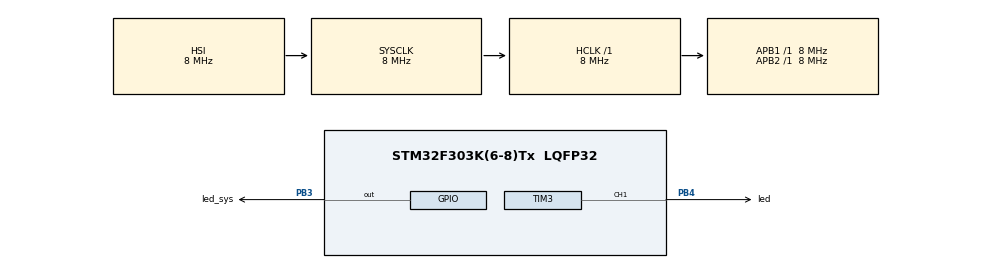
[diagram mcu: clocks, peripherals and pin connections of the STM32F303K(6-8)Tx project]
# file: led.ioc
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FREERTOS.Tasks01=defaultTask,0,128,StartDefaultTask,Default,NULL,Dynamic,NULL,NULL;pwm_task,-3,128,pwmTask,As weak,NULL,Dynamic,NULL,NULL
Mcu.Family=STM32F3
Mcu.Name=STM32F303K(6-8)Tx
Mcu.Package=LQFP32
NVIC.PriorityGroup=NVIC_PRIORITYGROUP_4
PA13.GPIO_Label=SWDIO
PA13.Signal=SYS_JTMS-SWDIO
PA14.GPIO_Label=SWCLK
PA14.Signal=SYS_JTCK-SWCLK
PA15.GPIO_Label=VCP_RX
PA15.Signal=USART2_RX
PA2.GPIO_Label=VCP_TX
PA2.Signal=USART2_TX
PB3.GPIO_Label=led_sys
PB3.Signal=GPIO_Output
PB4.GPIO_Label=led
PB4.GPIO_ModeDefaultPP=GPIO_MODE_AF_PP
PB4.Signal=S_TIM3_CH1
PF0\ /\ OSC_IN.GPIO_Label=MCO
PF0\ /\ OSC_IN.Signal=RCC_OSC_IN
ProjectManager.HeapSize=0x200
ProjectManager.StackSize=0x400
ProjectManager.TargetToolchain=Makefile
RCC.AHBFreq_Value=8000000
RCC.APB1Freq_Value=8000000
RCC.APB1TimFreq_Value=8000000
RCC.APB2Freq_Value=8000000
RCC.CortexFreq_Value=8000000
RCC.HSE_VALUE=8000000
RCC.HSI_VALUE=8000000
RCC.SYSCLKFreq_VALUE=8000000
SH.S_TIM3_CH1.0=TIM3_CH1,PWM Generation1 CH1
TIM3.AutoReloadPreload=TIM_AUTORELOAD_PRELOAD_DISABLE
TIM3.Channel-PWM\ Generation1\ CH1=TIM_CHANNEL_1
TIM3.ClockDivision=TIM_CLOCKDIVISION_DIV1
TIM3.CounterMode=TIM_COUNTERMODE_UP
TIM3.Period=999
TIM3.Prescaler=99
TIM3.Pulse-PWM\ Generation1\ CH1=249
VP_FREERTOS_VS_ENABLE.Mode=Enabled
board=NUCLEO-F303K8

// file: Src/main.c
/**
  ******************************************************************************
  * File Name          : main.c
  * Description        : Main program body
  ******************************************************************************
  * This notice applies to any and all portions of this file
  * that are not between comment pairs USER CODE BEGIN and
  * USER CODE END. Other portions of this file, whether
  * inserted by the user or by software development tools
  * are owned by their respective copyright owners.
  *
  * Copyright (c) 2017 STMicroelectronics International N.V.
  * All rights reserved.
  *
  * Redistribution and use in source and binary forms, with or without
  * modification, are permitted, provided that the following conditions are met:
  *
  * 1. Redistribution of source code must retain the above copyright notice,
  *    this list of conditions and the following disclaimer.
  * 2. Redistributions in binary form must reproduce the above copyright notice,
  *    this list of conditions and the following disclaimer in the documentation
  *    and/or other materials provided with the distribution.
  * 3. Neither the name of STMicroelectronics nor the names of other
  *    contributors to this software may be used to endorse or promote products
  *    derived from this software without specific written permission.
  * 4. This software, including modifications and/or derivative works of this
  *    software, must execute solely and exclusively on microcontroller or
  *    microprocessor devices manufactured by or for STMicroelectronics.
  * 5. Redistribution and use of this software other than as permitted under
  *    this license is void and will automatically terminate your rights under
  *    this license.
  *
  * THIS SOFTWARE IS PROVIDED BY STMICROELECTRONICS AND CONTRIBUTORS "AS IS"
  * AND ANY EXPRESS, IMPLIED OR STATUTORY WARRANTIES, INCLUDING, BUT NOT
  * LIMITED TO, THE IMPLIED WARRANTIES OF MERCHANTABILITY, FITNESS FOR A
  * PARTICULAR PURPOSE AND NON-INFRINGEMENT OF THIRD PARTY INTELLECTUAL PROPERTY
  * RIGHTS ARE DISCLAIMED TO THE FULLEST EXTENT PERMITTED BY LAW. IN NO EVENT
  * SHALL STMICROELECTRONICS OR CONTRIBUTORS BE LIABLE FOR ANY DIRECT, INDIRECT,
  * INCIDENTAL, SPECIAL, EXEMPLARY, OR CONSEQUENTIAL DAMAGES (INCLUDING, BUT NOT
  * LIMITED TO, PROCUREMENT OF SUBSTITUTE GOODS OR SERVICES; LOSS OF USE, DATA,
  * OR PROFITS; OR BUSINESS INTERRUPTION) HOWEVER CAUSED AND ON ANY THEORY OF
  * LIABILITY, WHETHER IN CONTRACT, STRICT LIABILITY, OR TORT (INCLUDING
  * NEGLIGENCE OR OTHERWISE) ARISING IN ANY WAY OUT OF THE USE OF THIS SOFTWARE,
  * EVEN IF ADVISED OF THE POSSIBILITY OF SUCH DAMAGE.
  *
  ******************************************************************************
  */
#include "main.h"
#include "stm32f3xx_hal.h"
#include "cmsis_os.h"

TIM_HandleTypeDef htim3;

osThreadId defaultTaskHandle;
osThreadId pwm_taskHandle;

/* USER CODE BEGIN PV */
/* Private variables ---------------------------------------------------------*/

/* USER CODE END PV */

void SystemClock_Config(void);
static void MX_GPIO_Init(void);
static void MX_TIM3_Init(void);
void StartDefaultTask(void const * argument);
void pwmTask(void const * argument);
void HAL_TIM_MspPostInit(TIM_HandleTypeDef *htim);

/* USER CODE BEGIN PFP */
/* Private function prototypes -----------------------------------------------*/

/* USER CODE END PFP */

int main(void)
{

  /* MCU Configuration----------------------------------------------------------*/

  /* Reset of all peripherals, Initializes the Flash interface and the Systick. */
  HAL_Init();

  /* Configure the system clock */
  SystemClock_Config();

  /* Initialize all configured peripherals */
  MX_GPIO_Init();
  MX_TIM3_Init();

  /* Create the thread(s) */
  /* definition and creation of defaultTask */
  osThreadDef(defaultTask, StartDefaultTask, osPriorityNormal, 0, 128);
  defaultTaskHandle = osThreadCreate(osThread(defaultTask), NULL);

  /* definition and creation of pwm_task */
  osThreadDef(pwm_task, pwmTask, osPriorityIdle, 0, 128);
  pwm_taskHandle = osThreadCreate(osThread(pwm_task), NULL);

  /* Start scheduler */
  osKernelStart();

  /* We should never get here as control is now taken by the scheduler */

  /* Infinite loop */
  while (1)
  {

  }

}

/** System Clock Configuration
*/
void SystemClock_Config(void)
{

  RCC_OscInitTypeDef RCC_OscInitStruct;
  RCC_ClkInitTypeDef RCC_ClkInitStruct;

    /**Initializes the CPU, AHB and APB busses clocks
    */
  RCC_OscInitStruct.OscillatorType = RCC_OSCILLATORTYPE_HSI;
  RCC_OscInitStruct.HSIState = RCC_HSI_ON;
  RCC_OscInitStruct.HSICalibrationValue = 16;
  RCC_OscInitStruct.PLL.PLLState = RCC_PLL_NONE;
  if (HAL_RCC_OscConfig(&RCC_OscInitStruct) != HAL_OK)
  {
    _Error_Handler(__FILE__, __LINE__);
  }

    /**Initializes the CPU, AHB and APB busses clocks
    */
  RCC_ClkInitStruct.ClockType = RCC_CLOCKTYPE_HCLK|RCC_CLOCKTYPE_SYSCLK
                              |RCC_CLOCKTYPE_PCLK1|RCC_CLOCKTYPE_PCLK2;
  RCC_ClkInitStruct.SYSCLKSource = RCC_SYSCLKSOURCE_HSI;
  RCC_ClkInitStruct.AHBCLKDivider = RCC_SYSCLK_DIV1;
  RCC_ClkInitStruct.APB1CLKDivider = RCC_HCLK_DIV1;
  RCC_ClkInitStruct.APB2CLKDivider = RCC_HCLK_DIV1;

  if (HAL_RCC_ClockConfig(&RCC_ClkInitStruct, FLASH_LATENCY_0) != HAL_OK)
  {
    _Error_Handler(__FILE__, __LINE__);
  }

    /**Configure the Systick interrupt time
    */
  HAL_SYSTICK_Config(HAL_RCC_GetHCLKFreq()/1000);

    /**Configure the Systick
    */
  HAL_SYSTICK_CLKSourceConfig(SYSTICK_CLKSOURCE_HCLK);

  /* SysTick_IRQn interrupt configuration */
  HAL_NVIC_SetPriority(SysTick_IRQn, 15, 0);
}

/* TIM3 init function */
static void MX_TIM3_Init(void)
{

  TIM_MasterConfigTypeDef sMasterConfig;
  TIM_OC_InitTypeDef sConfigOC;

  htim3.Instance = TIM3;
  htim3.Init.Prescaler = 99;
  htim3.Init.CounterMode = TIM_COUNTERMODE_UP;
  htim3.Init.Period = 999;
  htim3.Init.ClockDivision = TIM_CLOCKDIVISION_DIV1;
  htim3.Init.AutoReloadPreload = TIM_AUTORELOAD_PRELOAD_DISABLE;
  if (HAL_TIM_PWM_Init(&htim3) != HAL_OK)
  {
    _Error_Handler(__FILE__, __LINE__);
  }

  sMasterConfig.MasterOutputTrigger = TIM_TRGO_RESET;
  sMasterConfig.MasterSlaveMode = TIM_MASTERSLAVEMODE_DISABLE;
  if (HAL_TIMEx_MasterConfigSynchronization(&htim3, &sMasterConfig) != HAL_OK)
  {
    _Error_Handler(__FILE__, __LINE__);
  }

  sConfigOC.OCMode = TIM_OCMODE_PWM1;
  sConfigOC.Pulse = 249;
  sConfigOC.OCPolarity = TIM_OCPOLARITY_HIGH;
  sConfigOC.OCFastMode = TIM_OCFAST_DISABLE;
  if (HAL_TIM_PWM_ConfigChannel(&htim3, &sConfigOC, TIM_CHANNEL_1) != HAL_OK)
  {
    _Error_Handler(__FILE__, __LINE__);
  }

  HAL_TIM_MspPostInit(&htim3);

}

/** Configure pins as
        * Analog
        * Input
        * Output
        * EVENT_OUT
        * EXTI
     PA2   ------> USART2_TX
     PA15   ------> USART2_RX
*/
static void MX_GPIO_Init(void)
{

  GPIO_InitTypeDef GPIO_InitStruct;

  /* GPIO Ports Clock Enable */
  __HAL_RCC_GPIOF_CLK_ENABLE();
  __HAL_RCC_GPIOA_CLK_ENABLE();
  __HAL_RCC_GPIOB_CLK_ENABLE();

  /*Configure GPIO pin Output Level */
  HAL_GPIO_WritePin(led_sys_GPIO_Port, led_sys_Pin, GPIO_PIN_RESET);

  /*Configure GPIO pins : VCP_TX_Pin VCP_RX_Pin */
  GPIO_InitStruct.Pin = VCP_TX_Pin|VCP_RX_Pin;
  GPIO_InitStruct.Mode = GPIO_MODE_AF_PP;
  GPIO_InitStruct.Pull = GPIO_NOPULL;
  GPIO_InitStruct.Speed = GPIO_SPEED_FREQ_HIGH;
  GPIO_InitStruct.Alternate = GPIO_AF7_USART2;
  HAL_GPIO_Init(GPIOA, &GPIO_InitStruct);

  /*Configure GPIO pin : led_sys_Pin */
  GPIO_InitStruct.Pin = led_sys_Pin;
  GPIO_InitStruct.Mode = GPIO_MODE_OUTPUT_PP;
  GPIO_InitStruct.Pull = GPIO_NOPULL;
  GPIO_InitStruct.Speed = GPIO_SPEED_FREQ_LOW;
  HAL_GPIO_Init(led_sys_GPIO_Port, &GPIO_InitStruct);

}

/* StartDefaultTask function */
void StartDefaultTask(void const * argument)
{

  /* USER CODE BEGIN 5 */
    HAL_TIM_Base_Start(&htim3);
    HAL_TIM_PWM_Start(&htim3, TIM_CHANNEL_1);

  /* Infinite loop */
  for(;;)
  {
    HAL_GPIO_TogglePin(led_sys_GPIO_Port, led_sys_Pin);
    osDelay(1000);
  }
  /* USER CODE END 5 */
}

/* pwmTask function */
__weak void pwmTask(void const * argument)
{
  for(;;)
  {
    osDelay(1);
  }
}

void _Error_Handler(char * file, int line)
{
  while(1)
  {
  }
}

/************************ (C) COPYRIGHT STMicroelectronics *****END OF FILE****/

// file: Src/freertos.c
/**
  ******************************************************************************
  * File Name          : freertos.c
  * Description        : Code for freertos applications
  ******************************************************************************
  * This notice applies to any and all portions of this file
  * that are not between comment pairs USER CODE BEGIN and
  * USER CODE END. Other portions of this file, whether
  * inserted by the user or by software development tools
  * are owned by their respective copyright owners.
  *
  * Copyright (c) 2017 STMicroelectronics International N.V.
  * All rights reserved.
  *
  * Redistribution and use in source and binary forms, with or without
  * modification, are permitted, provided that the following conditions are met:
  *
  * 1. Redistribution of source code must retain the above copyright notice,
  *    this list of conditions and the following disclaimer.
  * 2. Redistributions in binary form must reproduce the above copyright notice,
  *    this list of conditions and the following disclaimer in the documentation
  *    and/or other materials provided with the distribution.
  * 3. Neither the name of STMicroelectronics nor the names of other
  *    contributors to this software may be used to endorse or promote products
  *    derived from this software without specific written permission.
  * 4. This software, including modifications and/or derivative works of this
  *    software, must execute solely and exclusively on microcontroller or
  *    microprocessor devices manufactured by or for STMicroelectronics.
  * 5. Redistribution and use of this software other than as permitted under
  *    this license is void and will automatically terminate your rights under
  *    this license.
  *
  * THIS SOFTWARE IS PROVIDED BY STMICROELECTRONICS AND CONTRIBUTORS "AS IS"
  * AND ANY EXPRESS, IMPLIED OR STATUTORY WARRANTIES, INCLUDING, BUT NOT
  * LIMITED TO, THE IMPLIED WARRANTIES OF MERCHANTABILITY, FITNESS FOR A
  * PARTICULAR PURPOSE AND NON-INFRINGEMENT OF THIRD PARTY INTELLECTUAL PROPERTY
  * RIGHTS ARE DISCLAIMED TO THE FULLEST EXTENT PERMITTED BY LAW. IN NO EVENT
  * SHALL STMICROELECTRONICS OR CONTRIBUTORS BE LIABLE FOR ANY DIRECT, INDIRECT,
  * INCIDENTAL, SPECIAL, EXEMPLARY, OR CONSEQUENTIAL DAMAGES (INCLUDING, BUT NOT
  * LIMITED TO, PROCUREMENT OF SUBSTITUTE GOODS OR SERVICES; LOSS OF USE, DATA,
  * OR PROFITS; OR BUSINESS INTERRUPTION) HOWEVER CAUSED AND ON ANY THEORY OF
  * LIABILITY, WHETHER IN CONTRACT, STRICT LIABILITY, OR TORT (INCLUDING
  * NEGLIGENCE OR OTHERWISE) ARISING IN ANY WAY OUT OF THE USE OF THIS SOFTWARE,
  * EVEN IF ADVISED OF THE POSSIBILITY OF SUCH DAMAGE.
  *
  ******************************************************************************
  */

#include "FreeRTOS.h"
#include "task.h"

/* USER CODE BEGIN Includes */
#include "cmsis_os.h" // pour osDelay
#include "main.h" // pour les macro definies par stm32cube
#include "stm32f3xx_hal.h" // pour tous les trucs de la HAL
/* USER CODE END Includes */

/* USER CODE BEGIN Variables */
extern TIM_HandleTypeDef htim3; // pour pouvoir utiliser l'instance de htim3
/* USER CODE END Variables */

/* USER CODE BEGIN FunctionPrototypes */
void user_pwm_setvalue(uint16_t value)
{
    TIM_OC_InitTypeDef sConfigOC;

    sConfigOC.OCMode = TIM_OCMODE_PWM1;
    sConfigOC.Pulse = value;
    sConfigOC.OCPolarity = TIM_OCPOLARITY_HIGH;
    sConfigOC.OCFastMode = TIM_OCFAST_DISABLE;
    HAL_TIM_PWM_ConfigChannel(&htim3, &sConfigOC, TIM_CHANNEL_1);
    HAL_TIM_PWM_Start(&htim3, TIM_CHANNEL_1);
}

/* USER CODE END FunctionPrototypes */

/* Hook prototypes */

/* USER CODE BEGIN Application */
void pwmTask(void const * argument)
{
  /* USER CODE BEGIN pwmTask */
  /* int pwm_value = 0;
  int step = 0; */

  HAL_TIM_Base_Start(&htim3);
  HAL_TIM_PWM_Start(&htim3, TIM_CHANNEL_1);
  int step = 0;
  int pwm_value = 0;

  /* Infinite loop */
  for(;;)
  {
    if(pwm_value == 0) step = 10;
    if(pwm_value == 7000) step = -10;
    pwm_value += step;
    //user_pwm_setvalue(pwm_value);
    osDelay(1);
  }
  /* USER CODE END pwmTask */
}

/* USER CODE END Application */

/************************ (C) COPYRIGHT STMicroelectronics *****END OF FILE****/
